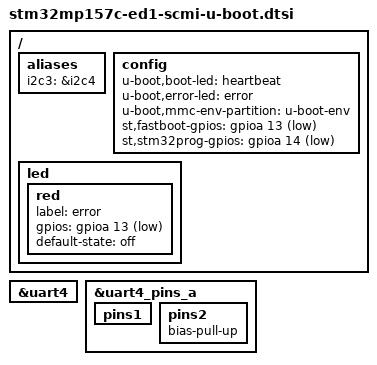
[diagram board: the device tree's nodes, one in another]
// SPDX-License-Identifier: GPL-2.0-or-later OR BSD-3-Clause
/*
 * Copyright : STMicroelectronics 2022
 */

#include "stm32mp15-scmi-u-boot.dtsi"

/ {
	aliases {
		i2c3 = &i2c4;
	};

	config {
		u-boot,boot-led = "heartbeat";
		u-boot,error-led = "error";
		u-boot,mmc-env-partition = "u-boot-env";
		st,fastboot-gpios = <&gpioa 13 (GPIO_ACTIVE_LOW | GPIO_PULL_UP)>;
		st,stm32prog-gpios = <&gpioa 14 (GPIO_ACTIVE_LOW | GPIO_PULL_UP)>;
	};

	led {
		red {
			label = "error";
			gpios = <&gpioa 13 GPIO_ACTIVE_LOW>;
			default-state = "off";
			status = "okay";
		};
	};
};

&uart4 {
	bootph-all;
};

&uart4_pins_a {
	bootph-all;
	pins1 {
		bootph-all;
	};
	pins2 {
		bootph-all;
		/* pull-up on rx to avoid floating level */
		bias-pull-up;
	};
};
